# ISP6P5_ISIF register map
Vendor: Texas Instruments
Peripheral module from a debugger description file (folder TDA2Px).
Registers are 32-bit, access per field, reset 0x0 unless marked. A register's access mark holds for its fields unless they carry their own. Offsets are as the file gives them; lines under a group give offsets from that group; [hi:lo] are bit positions; {n}, {i} and the like mark numbered series; 'fields as' and 'values as' point back to an identical list; <NAME> marks a mode.

## ISP6P5_ISIF
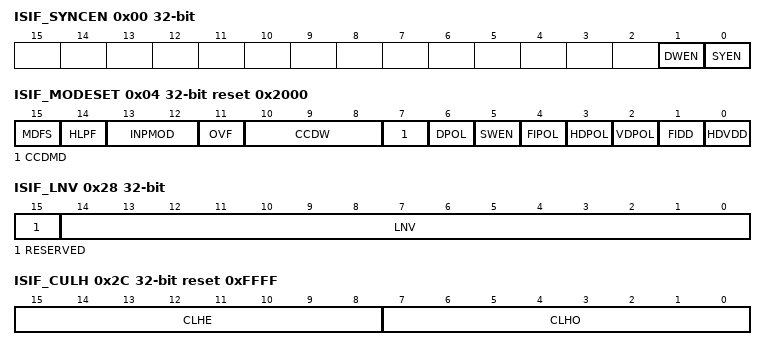
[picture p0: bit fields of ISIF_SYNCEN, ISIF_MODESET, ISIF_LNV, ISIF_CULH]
0x00 ISIF_SYNCEN
  [1] DWEN rw — Controls the storage of image sensor RAW data in memory. This bit is loaded with the timing of the internal VD signal: it becomes active starting at the lead of the VD signal that comes after 1 is written in this bit.
    0=NEWENUM1 (Disable); 1=NEWENUM2 (Enable)
  [0] SYEN rw — Controls ON/OFF of VD/HD output. Internal timing generator becomes active and VD/HD output begins starting when 1 is written in this bit. In case of input, VD/HD loading begins.
    0=NEWENUM1 (Disable); 1=NEWENUM2 (Enable)
0x04 ISIF_MODESET reset 0x2000
  [15] MDFS ro — Field Status This bit indicates the status of the current FLD signal when the ISIF module is in interlaced mode.
    0=NEWENUM1 (Odd field); 1=NEWENUM2 (Even field)
  [14] HLPF rw — Low pass filter enable. When this bit is enabled, a 3-tap (1/4 + 1/2 Z^-2 + 1/4 Z^?4) filtering process is performed on the sensor data.
    0=NEWENUM1 (Disable); 1=NEWENUM2 (Enable)
  [13:12] INPMOD rw — Data input mode:
    0=NEWENUM1 (RAW data); 1=NEWENUM2 (YCbCr 16bit); 3=NEWENUM4 (Reserved); 2=NEWENUM3 (YCbCr 8bit)
  [11] OVF rw — ISIF module write port overflow status bit If the write port of the ISIF module overflows when writing data to SDRAM, this bit will toggle. In OMAP4430 ES1.0, an interrupt (ISIF_OVF) is added to reflect the status of this bit and avoid polling.
    0=NEWENUM1 (No overflow pending (r) No action (w)); 1=NEWENUM2 (Overflow pending (r) Clear overflow (w))
  [10:8] CCDW rw — This bit enables to shift right (divide) the up-to-12-bit RAW data value when writing out to SDRAM. The effect is that the dynamic of the output signal is decreased. TheISIF_MODESET.CCDW, ISIF_HSIZE.ADCR, ISIF_HSIZE.HSIZE, ISIF_CCDCFG.BSWD, ISIF_CCDCFG.MSBINV, ISIF_CCDCFG.SDRPACK bit fields control how pixel data are stored to SDRAM.
    6=NEWENUM7 (Reserved); 1=NEWENUM2 (1-bit right shift out[15:0] = 00000 data[11:1]); 7=NEWENUM8 (Reserved); 0=NEWENUM1 (No shift out[15:0] = 0000 data[11:0]); 2=NEWENUM3 (2-bit right shift out[15:0] = 000000 data[11:2]); 4=NEWENUM5 (4-bit right shift out[15:0] = 00000000 data[11:4]); 5=NEWENUM6 (Reserved); 3=NEWENUM4 (3-bit right shift out[15:0] = 0000000 data[11:3])
  [7] CCDMD rw — Field mode: This bit selects the type of image sensor: interlaced or progressive
    0=NEWENUM1 (Progressive image sensor); 1=NEWENUM2 (Interlaced image sensor)
  [6] DPOL rw — Image sensor input data polarity
    0=NEWENUM1 (No change); 1=NEWENUM2 (One's complement)
  [5] SWEN rw — External WEN selection In case this bit and SYNCEN.DWEN are set to 1, the external WEN signal is used to store image sensor data to memory.
    0=NEWENUM1 (WEN not used); 1=NEWENUM2 (Use external WEN)
  [4] FIPOL rw — FLD Signal Polarity
    0=NEWENUM1 (Positive); 1=NEWENUM2 (Negative)
  [3] HDPOL rw — HD Sync Signal Polarity
    0=NEWENUM1 (Positive); 1=NEWENUM2 (Negative)
  [2] VDPOL rw — VD Sync Signal Polarity
    0=NEWENUM1 (Positive); 1=NEWENUM2 (Negative)
  [1] FIDD rw — FLD Signal Direction There shall be at least three clock cycles between the time this bit is modified and the HD/VD pulse for start of frame comes.
    0=NEWENUM1 (Input); 1=NEWENUM2 (Output)
  [0] HDVDD rw — VD,HD Sync Signal Direction There shall be at least three clock cycles between the time this bit is modified and the HD/VD pulse for start of frame comes.
    0=NEWENUM1 (Input); 1=NEWENUM2 (Output)
0x08 ISIF_HDW
  [11:0] HDW rw — HD width: Sets width of HD. HD width = HDW + 1 clock
0x0C ISIF_VDW
  [11:0] VDW rw — VD width : Sets width of VD. VD width = VDW + 1 line
0x10 ISIF_PPLN
  [15:0] PPLN rw — Pixels per line Number of pixel clock periods in one line HD period = PPLN+1 pixel clocks. PPLN is not used when HD and VD are inputs, i.e. when VDHDOUT in MODESET is cleared to '0'. *This bit field is latched by VD.
0x14 ISIF_LPFR — Line per Frame/Field
  [15:0] LPFR rw — Half lines per filed or frame Sets number of half lines per frame or field. VD period = (LPFR+1)/2 lines. LPFR is not used when HD and are inputs, i.e. when VDHDOUT in MODESET is cleared to '0'. *This bit field is latched by VD.
0x18 ISIF_SPH — Start Pixel Horizontal
  [14:0] SPH rw — The first pixel in a line to be stored to memory.
0x1C ISIF_LNH
  [14:0] LNH rw — Number of pixels in an line to be stored to memory. Number of pixels = LNH + 1. The number of pixels actually written to SDRAM is always a multiple of 16. For example, if CULH=0xFFFF, the actual number of output is 16 x floor((LNH+1)/16). If CULH is not 0xFFFF, the actual output is 16 x floor(w/16), where w is the number of pixels after horizontal culling specified by CULH.
0x20 ISIF_SLV0
  [14:0] SLV0 rw — Start Line, Vertical (Field 0) Sets line at which data output to SDRAM will begin, measured from the start of VD *This bit field is latched by VD.
0x24 ISIF_SLV1
  [14:0] SLV1 rw — Start Line, Vertical (Field 1) Sets line at which data output to SDRAM will begin, measured from the start of VD *This bit field is latched by VD.
0x28 ISIF_LNV
  [15] RESERVED ro — The number of lines to be stored to SDRAM.
  [14:0] LNV rw — The number of lines to be stored to memory. Number of lines = LNV + 1
0x2C ISIF_CULH reset 0xFFFF — This register specifies horizontal culling. Please also refer to for the effect to the number of pixels written to SDRAM.
  [15:8] CLHE rw — Culling Pattern in EVEN Line: Sets culling pattern when data is loaded into memory (even lines). Example:0xAA: 1 / 2 horizontal direction culling. LSB becomes left side on screen.
    0=NEWENUM1 (Pixel invalid); 1=NEWENUM2 (Pixel valid)
  [7:0] CLHO rw — Culling Pattern in ODD Line: Sets culling pattern when data is loaded into memory (odd lines).
    0=NEWENUM1 (Pixel invalid); 1=NEWENUM2 (Pixel valid)
0x30 ISIF_CULV reset 0xFF
  [7:0] CULV rw — Culling Pattern in Vertical Line Note: CULV[0] must be 1 for proper operation. Example:0x11: 1/4 vertical direction culling. LSB becomes top side on screen.
    0=NEWENUM1 (Pixel invalid); 1=NEWENUM2 (Pixel valid)
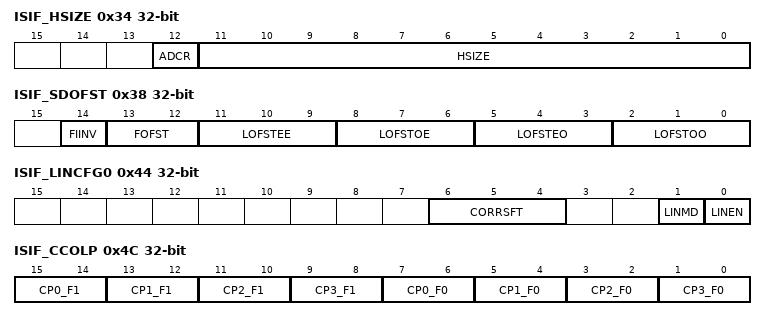
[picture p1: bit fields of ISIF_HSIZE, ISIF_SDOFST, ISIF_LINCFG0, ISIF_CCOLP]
0x34 ISIF_HSIZE — SDRAM OUTPUT CTRL REGISTER
  [12] ADCR rw — SDRAM address decrement. By setting this bit, memory address in a line is automatically decreased so that a line can be Horizontally flipped in memory. TheISIF_MODESET.CCDW, ISIF_HSIZE.ADCR, ISIF_HSIZE.HSIZE, ISIF_CCDCFG.BSWD, ISIF_CCDCFG.MSBINV, ISIF_CCDCFG.SDRPACK bit fields control how pixel data are stored to SDRAM.
    0=NEWENUM1 (Address increment.); 1=NEWENUM2 (Address decrement.)
  [11:0] HSIZE rw — Memory address offset between the lines. Specify the offset in 32-byte units.
0x38 ISIF_SDOFST — SDRAM OUTPUT CTRL REGISTER
  [14] FIINV rw — FID polarity: This bit inverse a FID polarity.
    0=NEWENUM1 (No change); 1=NEWENUM2 (Inverse FID)
  [13:12] FOFST rw — Field line offset value in odd (FID = 1) field
    0=NEWENUM1 (+1 line); 1=NEWENUM2 (+2 lines); 3=NEWENUM4 (+4 lines); 2=NEWENUM3 (+3 lines)
  [11:9] LOFSTEE rw — Field line offset value applied after even line, even field (This value affects the first address of odd lines)
    6=NEWENUM7 (- 3 lines); 1=NEWENUM2 (+2 lines); 7=NEWENUM8 (- 4 lines); 0=NEWENUM1 (+1 line); 2=NEWENUM3 (+3 lines); 4=NEWENUM5 (- 1 line); 5=NEWENUM6 (- 2 lines); 3=NEWENUM4 (+4 lines)
  [8:6] LOFSTOE rw — Field line offset value applied after odd line, even field (This value affects the even lines)
    values as LOFSTEE
  [5:3] LOFSTEO rw — Field line offset value applied after even line, odd field (This value affects the first address of off lines)
    values as LOFSTEE
  [2:0] LOFSTOO rw — Field line offset value applied after odd line, odd field (This value affects the first address of even lines)
    values as LOFSTEE
0x3C ISIF_CADU — SDRAM OUTPUT CTRL REGISTER
  [10:0] CADU rw — Memory Address (Upper 11-bits): Specifies the memory destination address. The actual address is the value set here multiplied by 32bytes.
0x40 ISIF_CADL — SDRAM OUTPUT CTRL REGISTER
  [15:0] CADL rw — Memory Address (Lower 16-bits): Specifies the memory destination address. The actual address is the value set here multiplied by 32bytes.
0x44 ISIF_LINCFG0 — INPUT LINEARIZATION CTRL REGISTER
  [6:4] CORRSFT rw — Shift up value for the correction value (S10).
    {v}=NEWENUM{v+1} ({v}-bit left shift) (v=1..6); 7=NEWENUM8 (Reserved); 0=NEWENUM1 (No shift)
  [1] LINMD rw — Linearization Mode:
    0=NEWENUM1 (Uniform sampling); 1=NEWENUM2 (Non-uniform sampling)
  [0] LINEN rw — Linearization Enable:
    0=NEWENUM1 (Disable); 1=NEWENUM2 (Enable)
0x48 ISIF_LINCFG1 reset 0x400 — INPUT LINEARIZATION CTRL REGISTER
  [10:0] LUTSCL rw — Scale factor (U11Q10) for LUT input. Range: 0 ? 1+1023/1024 It?s applied to the Input Data before looking up the correction factor. The scale factor is only applied to the table input. It?s not applied when using the input value to compute the output.
0x4C ISIF_CCOLP
  [all] fields
    0=NEWENUM1 (R / Ye); 1=NEWENUM2 (Gr / Cy); 3=NEWENUM4 (B / Mg); 2=NEWENUM3 (Gb / G)
  [15:14] CP0_F1 rw — Specifies color pattern for pixel position 0 (Field 1) Pixel position 0 corresponds to pixel count=0 at even line in case of CFAP=?0?, and to pixel count=0 in case of CFAP=?1?.
  [13:12] CP1_F1 rw — Specifies color pattern for pixel position 1 (Field 1) Pixel position 1 corresponds to pixel count=1 at even line in case of CFAP=?0?, and to pixel count=1 in case of CFAP=?1?.
  [11:10] CP2_F1 rw — Specifies color pattern for pixel position 2 (Field 1) Pixel position 2 corresponds to pixel count=0 at odd line in case of CFAP=?0?, and to pixel count=2 in case of CFAP=?1?.
  [9:8] CP3_F1 rw — Specifies color pattern for pixel position 3 (Field 1) Pixel position 3 corresponds to pixel count=1 at odd line in case of CFAP=?0?. Not applicable for CFAP=?1?.
  [7:6] CP0_F0 rw — Specifies color pattern for pixel position 0 (Field 0) Pixel position 0 corresponds to pixel count=0 at even line in case of CFAP=?0?, and to pixel count=0 in case of CFAP=?1?.
  [5:4] CP1_F0 rw — Specifies color pattern for pixel position 1 (Field 0) Pixel position 1 corresponds to pixel count=1 at even line in case of CFAP=?0?, and to pixel count=1 in case of CFAP=?1?.
  [3:2] CP2_F0 rw — Specifies color pattern for pixel position 2 (Field 0) Pixel position 2 corresponds to pixel count=0 at odd line in case of CFAP=?0?, and to pixel count=2 in case of CFAP=?1?.
  [1:0] CP3_F0 rw — Specifies color pattern for pixel position 3 (Field 0) Pixel position 3 corresponds to pixel count=1 at odd line in case of CFAP=?0?. Not applicable for CFAP=?1?.
0x50 ISIF_CRGAIN reset 0x200
  [11:0] CGR rw — R/Ye gain: Performs gain adjustment on image sensor data. U12Q9. Range: 0 ? 7+511/512
0x54 ISIF_CGRGAIN reset 0x200
  [11:0] CGGR rw — Gr/Cy gain: Performs gain adjustment on image sensor data. U12Q9. Range: 0 ? 7+511/512
0x58 ISIF_CGBGAIN reset 0x200
  [11:0] CGGB rw — Gb/Cy gain: Performs gain adjustment on image sensor data. U12Q9. Range: 0 ? 7+511/512
0x5C ISIF_CBGAIN reset 0x200
  [11:0] CGB rw — B/Mg gain: Performs gain adjustment on image sensor data. U12Q9. Range: 0 ? 7+511/512
0x60 ISIF_COFSTA
  [11:0] COFT rw — Image sensor offset: Performs offset value adjustment on image sensor data (0~4095).
0x64 ISIF_FLSHCFG0 — Not used in MONICA and OMAP4
  [0] FLSHEN rw — Flash timing signal enable This bit is automatically cleared to '0' at VD timing.
    0=NEWENUM1 (Disable); 1=NEWENUM2 (Enable)
0x68 ISIF_FLSHCFG1 — Not used in MONICA and OMAP4
  [14:0] SFLSH rw — Start line to set the FLASH timing signal.
0x6C ISIF_FLSHCFG2 — Not used in MONICA and OMAP4
  [15:0] VFLSH rw — Valid width of the FLASH timing signal. Valid width = Crystal-clock x 2 x (VFLSH + 1)
{0x70+4i} ISIF_VDINT{i} (i=0..2)
  [14:0] CVD{i} rw — VD{i} Interrupt timing in a field (line number).
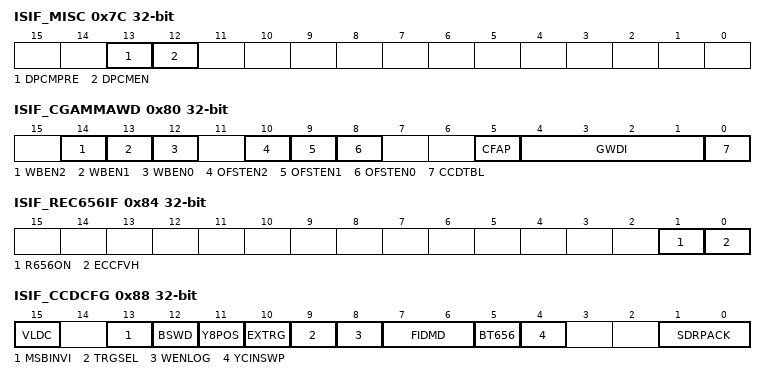
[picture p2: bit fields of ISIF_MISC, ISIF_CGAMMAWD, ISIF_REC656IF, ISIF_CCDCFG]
0x7C ISIF_MISC
  [13] DPCMPRE rw — Selects Predictor for DPCM Encoder (12-8)
    0=NEWENUM1 (Predictor 1); 1=NEWENUM2 (Predictor 2)
  [12] DPCMEN rw — Enables DPCM Encoding (12-8)
    0=NEWENUM1 (Disable); 1=NEWENUM2 (Enable)
0x80 ISIF_CGAMMAWD
  [14] WBEN2 rw — White Balance Enable for H3A
    0=NEWENUM1 (Disable); 1=NEWENUM2 (Enable)
  [13] WBEN1 rw — White Balance Enable for IPIPE
    0=NEWENUM1 (Disable); 1=NEWENUM2 (Enable)
  [12] WBEN0 rw — White Balance Enable for memory capture
    0=NEWENUM1 (Disable); 1=NEWENUM2 (Enable)
  [10] OFSTEN2 rw — Offset control Enable for H3A
    0=NEWENUM1 (Disable); 1=NEWENUM2 (Enable)
  [9] OFSTEN1 rw — Offset control Enable for IPIPE
    0=NEWENUM1 (Disable); 1=NEWENUM2 (Enable)
  [8] OFSTEN0 rw — Offset control Enable for SDRAM capture
    0=NEWENUM1 (Disable); 1=NEWENUM2 (Enable)
  [5] CFAP rw — Selects CFA pattern
    0=NEWENUM1 (Mosaic color pattern. It should look like this. G R G R G R G R G R . . . B G B G B G B G B G . . . G R G R G R G R G R . . . . . . . . . . . . . . . . . . . . . . . . . . . . . . . . .); 1=NEWENUM2 (Stripe color pattern. It should look like this. R G B R G B R G B . . . R G B R G B R G B . . . R G B R G B R G B . . . . . . . . . . . . . . . . . . . . . . . . . . . . . . . . .)
  [4:1] GWDI rw — Selects MSB position of Input Data
    {v}=NEWENUM{v+1} (Reserved) (v=9..15); 1=NEWENUM2 (bit 14); 7=NEWENUM8 (bit 8); 6=NEWENUM7 (bit 9); 0=NEWENUM1 (bit 15); 5=NEWENUM6 (bit 10); 4=NEWENUM5 (bit 11); 2=NEWENUM3 (bit 13); 3=NEWENUM4 (bit 12); 8=NEWENUM9 (bit 7)
  [0] CCDTBL rw — On/Off control of A-law table for SDRAM capture
    0=NEWENUM1 (Disable); 1=NEWENUM2 (Enable)
0x84 ISIF_REC656IF — INPUT CONFIG REGISTER
  [1] R656ON rw — CCIR Rec.656 interface mode
    0=NEWENUM1 (Disable); 1=NEWENUM2 (Enable)
  [0] ECCFVH rw — Error correction of FVH code
    0=NEWENUM1 (Disable); 1=NEWENUM2 (Enable)
0x88 ISIF_CCDCFG
  [15] VLDC rw — On/off control of CPU registers re-synchronize function by VSYNC. All the others are shadowed registers, where register values are updated at V-sync timing by default. If VDLC=1, ISIF register values are updated immediately after register write just like non-shadowed registers.
    0=NEWENUM1 (Enable); 1=NEWENUM2 (Disable)
  [13] MSBINVI rw — MSB inverse of CIN port when the data are captured to SDRAM. TheISIF_MODESET.CCDW, ISIF_HSIZE.ADCR, ISIF_HSIZE.HSIZE, ISIF_CCDCFG.BSWD, ISIF_CCDCFG.MSBINV, ISIF_CCDCFG.SDRPACK bit fields control how pixel data are stored to SDRAM.
    0=NEWENUM1 (Disable); 1=NEWENUM2 (Enable)
  [12] BSWD rw — On/off control of Byte SWAP function when SDRAM capturing. TheISIF_MODESET.CCDW, ISIF_HSIZE.ADCR, ISIF_HSIZE.HSIZE, ISIF_CCDCFG.BSWD, ISIF_CCDCFG.MSBINV, ISIF_CCDCFG.SDRPACK bit fields control how pixel data are stored to SDRAM.
    0=NEWENUM1 (Disable); 1=NEWENUM2 (Enable (swap))
  [11] Y8POS rw — Selects Y signal position when in 8bit input mode
    0=NEWENUM1 (even pixel); 1=NEWENUM2 (odd pixel)
  [10] EXTRG rw — Setting ?1? to this register, the SDRAM address is initialized at the rising edge of FID input signal or DWEN register.
  [9] TRGSEL rw — Select trigger source signal of SDRAM address initializing in case EXTRG=1.
    0=NEWENUM1 (DWEN register); 1=NEWENUM2 (FID input port)
  [8] WENLOG rw — Specifies the CCD valid area.
    0=NEWENUM1 (internal valid signal and WEN signal is ANDed logically.); 1=NEWENUM2 (internal valid signal and WEN signal is ORed logically.)
  [7:6] FIDMD rw — Specifies FID detection mode
    0=NEWENUM1 (latch the FID at the VSYNC timing); 1=NEWENUM2 (no latch the FID); 3=NEWENUM4 (Reserved); 2=NEWENUM3 (Reserved)
  [5] BT656 rw — Selects bit width of CCIR656. This bit applies only ifISIF_REC656IF.R656ON = 1.
    0=NEWENUM1 (8 bits); 1=NEWENUM2 (10 bits)
  [4] YCINSWP rw — The ISIF module has a 16-bit interface. When 16-bit YUV data are input, the luma data (YIN7-0) are expected to be on the 8 MS bits and the chroma (CIN7-0) data are expected to be on the LS bits. This bit enables to swap the 8 MS bits with the 8 LS bits of the interface in case the luma and chroma do not come in the correct order. Refer to the top-level ISIF block diagram.
    0=NEWENUM1 (YIN7-0 = Y signal / CIN7-0 = C signal); 1=NEWENUM2 (YIN7-0 = C signal / CIN7-0 = Y signal)
  [1:0] SDRPACK rw — This bit field selects how the data are stored to SDRAM. There can be 8, 12 or 16 bits per pixel. TheISIF_MODESET.CCDW, ISIF_HSIZE.ADCR, ISIF_HSIZE.HSIZE, ISIF_CCDCFG.BSWD, ISIF_CCDCFG.MSBINV, ISIF_CCDCFG.SDRPACK bit fields control how pixel data are stored to SDRAM.
    0=NEWENUM1 (16 bits / pixel); 1=NEWENUM2 (12 bits / pixel); 3=NEWENUM4 (Reserved); 2=NEWENUM3 (8 bits / pixel)
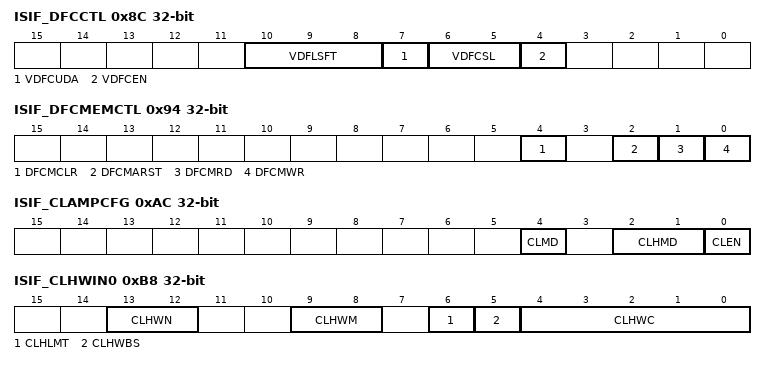
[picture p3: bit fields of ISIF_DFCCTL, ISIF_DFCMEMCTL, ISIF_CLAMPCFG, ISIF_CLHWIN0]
0x8C ISIF_DFCCTL — VERTICAL LINE DEFCT CTRL REGISTER
  [10:8] VDFLSFT rw — Vertical line Defect level shift value Defect Level (value to be subtracted from the data) is 8bit width, but can be up-shifted up to 6bits by VDFLSFT. Left shift value = VDFLSFT (Range: 0-6) Setting 7 to VDFLSFT is not allowed.
  [7] VDFCUDA rw — Vertical line Defect Correction upper pixels disable.
    0=NEWENUM1 (The whole line is corrected.); 1=NEWENUM2 (Pixels upper than the defect are not corrected.)
  [6:5] VDFCSL rw — Vertical line Defect Correction mode select.
    0=NEWENUM1 (Defect level subtraction. Just fed through if data are saturating.); 1=NEWENUM2 (Defect level subtraction. Horizontal interpolation ((i-2)+(i+2))/2 if data are saturating.); 3=NEWENUM4 (Reserved); 2=NEWENUM3 (Horizontal interpolation ((i-2)+(i+2))/2.)
  [4] VDFCEN rw — Vertical line Defect Correction enable. This bit field is latched by VD.
    0=NEWENUM1 (Disable); 1=NEWENUM2 (Enable)
0x90 ISIF_VDFSATLV — VERTICAL LINE DEFCT CTRL REGISTER
  [11:0] VDFSLV rw — Vertical line Defect Correction saturation level. VDFSLV is U12 (Range: 0 - 4,095).
0x94 ISIF_DFCMEMCTL — VERTICAL LINE DEFCT CTRL REGISTER
  [4] DFCMCLR rw — Defect correction. Memory clear. Writing ?1? to this bit clears the memory contents to all zero. It will be automatically cleared to `0` when the memory clear is completed.
  [2] DFCMARST rw — Defect correction. Memory address reset. Setting DFCMWR or DFCMRD with LSCMARST set starts memory access to address offset 0. DFCMARST is automatically cleared if data transfer completes. Setting DFCMWR or DFCMRD with LSCMARST cleared starts memory access to the next address.
    0=NEWENUM1 (Increment the memory address); 1=NEWENUM2 (Clear the memory address to offset 0)
  [1] DFCMRD rw — Defect correction. Memory read [for debug purpose] Writing ?1? to this bit starts reading from the memory. It will be automatically cleared when the data transfer is completed, and the data can be read from DFCMEM4-0.
  [0] DFCMWR rw — Defect correction. Memory write Writing ?1? to this bit starts writing to the memory. It will be automatically cleared when the data transfer is completed. DFCMEM4-0 should be set prior to the memory access.
0x98 ISIF_DFCMEM0 — Defect correction memory
  [12:0] DFCMEM0 rw — Defect correction memory 0 Sets V position of the defects.
0x9C ISIF_DFCMEM1 — Defect correction memory
  [12:0] DFCMEM1 rw — Defect correction memory 1 Sets H position of the defects.
0xA0 ISIF_DFCMEM2 — Defect correction memory
  [7:0] DFCMEM2 rw — Defect correction Memory 2 Set SUB1: Defect level of the Vertical line defect position (V = Vdefect). DFCMEM2 can be up shifted according to VDFLSFT, and subtracted from the data for Vertical line defect correction.
0xA4 ISIF_DFCMEM3 — Defect correction memory
  [7:0] DFCMEM3 rw — Defect correction Memory 3 Set SUB2: Defect level of the pixels upper than the Vertical line defect (V Vdefect). DFCMEM3 can be up shifted according to VDFLSFT, and subtracted from the data for Vertical line defect correction.
0xA8 ISIF_DFCMEM4 — Defect correction memory
  [7:0] DFCMEM4 rw — Memory 4 Set SUB3: Defect level of the pixels lower than the Vertical line defect (V Vdefect). DFCMEM4 can be up shifted according to VDFLSFT, and subtracted from the data for Vertical line defect correction.
0xAC ISIF_CLAMPCFG — BLACK CLAMP CTRL REGISTER
  [4] CLMD rw — Black clamp mode Clamp value can be calculated regardless of the color or can be calculated separately for each 4 colors.
    0=NEWENUM1 (Clamp value calculated regardless of the pixel color.); 1=NEWENUM2 (Clamp value calculated separately for each 4 colors.)
  [2:1] CLHMD rw — Horizontal Clamp mode
    0=NEWENUM1 (Horizontal clamp disabled. Only the Vertical clamp value is subtracted from the Image data.); 1=NEWENUM2 (Horizontal clamp value calculation enabled. The calculated Horizontal clamp value is subtracted from the Image data along with the Vertical clamp value.); 3=NEWENUM4 (Reserved); 2=NEWENUM3 (Horizontal clamp value not updated. The Horizontal clamp value used for the previous image is subtracted from the Image data along with the Vertical clamp value.)
  [0] CLEN rw — Black Clamp Enable Enables clamp value to be subtracted from Image data.
    0=NEWENUM1 (Disable); 1=NEWENUM2 (Enable)
0xB0 ISIF_CLDCOFST — BLACK CLAMP CTRL REGISTER
  [12:0] CLDC rw — DC offset for black clamp This value is added to the incoming pixels regardless whether optical black clamp is enabled (ISIF_CLAMPCFG.CLEN). This value is in S13Q0 format.
0xB4 ISIF_CLSV — BLACK CLAMP CTRL REGISTER
  [12:0] CLSV rw — Black Clamp Start position (V). Sets the line number where clamp value subtraction starts. Range: 0 - 8191
0xB8 ISIF_CLHWIN0 — BLACK CLAMP CTRL REGISTER
  [13:12] CLHWN rw — Horizontal Black clamp - Vertical dimension of a Window (2^N).
    0=NEWENUM1 (Window is 2 pixels tall (N=1)); 1=NEWENUM2 (Window is 4 pixels tall (N=2)); 3=NEWENUM4 (Window is 16 pixels tall (N=4)); 2=NEWENUM3 (Window is 8 pixels tall (N=3))
  [9:8] CLHWM rw — Horizontal Black clamp - Horizontal dimension of a Window (2^M).
    0=NEWENUM1 (Window is 32 pixels wide (M=5)); 1=NEWENUM2 (Window is 64 pixels wide (M=6)); 3=NEWENUM4 (Window is 256 pixels wide (M=8)); 2=NEWENUM3 (Window is 128 pixels wide (M=7))
  [6] CLHLMT rw — Horizontal Black clamp - Pixel value limitation for the Horizontal clamp value calculation. If this bit is set, the maximum pixel value to be used for the clamp value calculation would be limited to 1023. By setting this bit, the pixel value greater than 1023 will be replaced by the last pixel value which was equal to or less than 1023. In caseISIF_CLAMPCFG.CLMD=1 (4-color mode), the pixel value greater than 1023 will be replaced by the last pixel value of the same color which was equal to or less than 1023.
    0=NEWENUM1 (Limitation disabled); 1=NEWENUM2 (Limitation enabled)
  [5] CLHWBS rw — Horizontal Black clamp - Base Window select
    0=NEWENUM1 (The most left window); 1=NEWENUM2 (The most right window)
  [4:0] CLHWC rw — Horizontal Black clamp - Window count per color Window count = CLHWC+1 Range: 1 - 32
0xBC ISIF_CLHWIN1 — BLACK CLAMP CTRL REGISTER
  [12:0] CLHSH rw — Horizontal black clamp. Window Start position (H). Range: 0 - 8191
0xC0 ISIF_CLHWIN2 — BLACK CLAMP CTRL REGISTER
  [12:0] CLHSV rw — Horizontal black clamp. Window Start position (V). Range: 0 - 8191
0xC4 ISIF_CLVRV — BLACK CLAMP CTRL REGISTER
  [11:0] CLVRV rw — Vertical black clamp reset value. (U12) Range: 0 to 4095
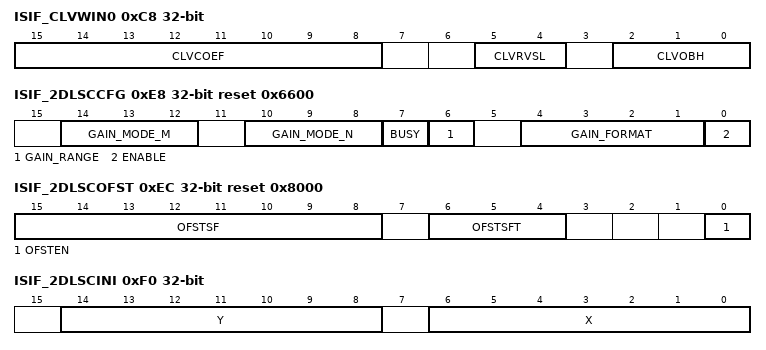
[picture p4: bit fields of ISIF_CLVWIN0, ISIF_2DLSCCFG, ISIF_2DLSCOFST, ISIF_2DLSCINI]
0xC8 ISIF_CLVWIN0 — BLACK CLAMP CTRL REGISTER
  [15:8] CLVCOEF rw — Vertical Black clamp - Line average coefficient (k). Set a coefficient which is applied to the line average for clamp value calculation. (1-k) is applied to the clamp value of the previous line. Vaue in the U8Q8 format, the range is 0 to 255/256.
  [5:4] CLVRVSL rw — Vertical Black clamp - reset value selection Select the reset value for the clamp value of the previous line
    0=NEWENUM1 (The base value calculated for Horizontal direction); 1=NEWENUM2 (Value set via the configuration register); 3=NEWENUM4 (Reserved); 2=NEWENUM3 (No update (same as the previous image))
  [2:0] CLVOBH rw — Vertical Black clamp - Optical Black H valid (2^L).
    6=NEWENUM7 (Reserved); 1=NEWENUM2 (4 pixels wide (L=2)); 7=NEWENUM8 (Reserved); 0=NEWENUM1 (2 pixels wide (L=1)); 2=NEWENUM3 (8 pixels wide (L=3)); 4=NEWENUM5 (32 pixels wide (L=5)); 5=NEWENUM6 (64 pixels wide (L=6)); 3=NEWENUM4 (16 pixels wide (L=4))
0xCC ISIF_CLVWIN1 — BLACK CLAMP CTRL REGISTER
  [12:0] CLVSH rw — Vertical black clamp. Window Start position (H). Range: 0 - 8191
0xD0 ISIF_CLVWIN2 — BLACK CLAMP CTRL REGISTER
  [12:0] CLVSV rw — Vertical black clamp. Window Start position (V). Range: 0 - 8191
0xD4 ISIF_CLVWIN3 — BLACK CLAMP CTRL REGISTER
  [12:0] CLVOBV rw — Vertical black clamp. Optical black V valid (V). Range: 0 - 8191
0xD8 ISIF_LSCHOFST — 2D Lens Shading Correction Register
  [13:0] HOFST rw — H direction Data offset for Lens Shading Correction. Range: 0-16,383 Not valid if the Formatter is enabled.
0xDC ISIF_LSCVOFST — 2D Lens Shading Correction Register
  [13:0] VOFST rw — V direction Data offset for Lens Shading Correction. Range: 0-16,383
0xE0 ISIF_LSCHVAL — 2D Lens Shading Correction Register
  [13:0] HVAL rw — Number of valid pixels in H direction. HVAL is for LSC. Number of valid pixels = HVAL+ 1
0xE4 ISIF_LSCVVAL — 2D Lens Shading Correction Register
  [13:0] VVAL rw — Number of valid lines in V direction. VVAL is for LSC. Number of valid lines = VVAL+ 1
0xE8 ISIF_2DLSCCFG reset 0x6600 — 2D Lens Shading Correction Register
  [14:12] GAIN_MODE_M rw — Define the horizontal dimension of a paxel. Possible values are listed below.
    6=NEWENUM7 (Paxel is 64 pixels tall (M=64)); 1=NEWENUM2 (Reserved); 7=NEWENUM8 (Paxel is 128 pixels tall (M=128)); 0=NEWENUM1 (Reserved); 2=NEWENUM3 (Reserved); 4=NEWENUM5 (Paxel is 16 pixels tall (M=16)); 5=NEWENUM6 (Paxel is 32 pixels tall (M=32)); 3=NEWENUM4 (Paxel is 8 pixels tall (M=8))
  [10:8] GAIN_MODE_N rw — Define the vertical dimension of a paxel. Possible values are listed below.
    6=NEWENUM7 (Paxel is 64 pixels tall (N=64)); 1=NEWENUM2 (Reserved); 7=NEWENUM8 (Paxel is 128 pixels tall (N=128)); 0=NEWENUM1 (Reserved); 2=NEWENUM3 (Reserved); 4=NEWENUM5 (Paxel is 16 pixels tall (N=16)); 5=NEWENUM6 (Paxel is 32 pixels tall (N=32)); 3=NEWENUM4 (Paxel is 8 pixels tall (N=8))
  [7] BUSY ro — Busy bit
    0=NEWENUM1 (Idle); 1=NEWENUM2 (Busy)
  [6] GAIN_RANGE rw — Define the range of gain table values. 0: 8-bit gain mode, GAIN table represents unsigned 8bit values 1: 16-bit gain mode. GAIN table is combined with OFST table to constitute 16 bit gain values. GAIN table represents MSB 8 bits, and OFST table represents LSB 8 bits. In 16-bit, offset table is loaded from memory. Offset control function is disabled. (OFSTEN is treated as zero in this mode.) This function is only for OMAP5430-ISP.
  [4:1] GAIN_FORMAT rw — Sets gain table format 16-bit mode is only for OMAP5430. For OMAP4, only 8-bit mode is available.
    13=NEWENUM14 (In 8-bit mode, Coded as 2-bit integer, 6-bit fraction + 1.0, Range from 1 to 4+63/64 In 16-bit mode, Coded as 6-bit integer and 10-bit fraction Range from 1 to 64+1023/1024); 1=NEWENUM2 (In 8-bit mode, Coded as 8-bit fraction + 1.0 of base, Range from 1 to 1+255/256 in 16-bit mode, Coded as 16-bit fraction + 1.0 of base, Range from 1 to 1+65535/65536); 7=NEWENUM8 (In 8-bit mode, Coded as 3-bit integer, 5-bit fraction + 1.0, Range from 1 to 8+31/32 In 16-bit mode, Coded as 3-bit integer, 13-bit fraction + 1.0, Range from 1 to 8+8191/8192); 6=NEWENUM7 (In 8-bit mode, Coded as 3-bit integer, 5-bit fraction, Range from 0 to 7+31/32 In 16-bit mode, Coded as 3-bit integer, 13-bit fraction, Range from 0 to 7+8191/8192); 0=NEWENUM1 (In 8-bit mode, Coded as 8-bit fraction Range from 0 to 255/256 In 16-bit mode, Coded as 16-bit fraction Range from 0 to 65535/65536); 5=NEWENUM6 (In 8-bit mode, Coded as 2-bit integer, 6-bit fraction + 1.0, Range from 1 to 4+63/64 In 16-bit mode, Coded as 2-bit integer, 14-bit fraction + 1.0, Range from 1 to 4+16383/16384); 10=NEWENUM11 (In 8-bit mode, Coded as 1-bit integer, 7-bit fraction, Range from 0 to 1+127/128 In 16-bit mode, Coded as 5-bit integer and 11-bit fraction Range from 0 to 31+2047/2048); 9=NEWENUM10 (In 8-bit mode, Coded as 8-bit fraction + 1.0 of base, Range from 1 to 1+255/256 In 16-bit mode, Coded as 4-bit integer and 12-bit fraction Range from 1 to 16+4095/4096); 11=NEWENUM12 (In 8-bit mode, Coded as 1-bit integer, 7-bit fraction + 1.0, Range from 1 to 2+127/128 In 16-bit mode, Coded as 5-bit integer and 11-bit fraction + 1.0, Range from 1 to 32+2047/2048); 4=NEWENUM5 (In 8-bit mode, Coded as 2-bit integer, 6-bit fraction, Range from 0 to 3+63/64 In 16-bit mode, Coded as 2-bit integer, 14-bit fraction, Range from 0 to 3+16383/16384); 2=NEWENUM3 (In 8-bit mode, Coded as 1-bit integer, 7-bit fraction, Range from 0 to 1+127/128 In 16-bit mode, Coded as 1-bit integer, 15-bit fraction, Range from 0 to 1+32767/32768); 15=NEWENUM16 (In 8-bit mode, Coded as 3-bit integer, 5-bit fraction + 1.0, Range from 1 to 8+31/32 In 16-bit mode, Coded as 7-bit integer and 9-bit fraction + 1.0, Range from 1 to 128+511/512); 12=NEWENUM13 (In 8-bit mode, Coded as 2-bit integer, 6-bit fraction, Range from 0 to 3+63/64 In 16-bit mode, Coded as 6-bit integer and 10-bit fraction Range from 0 to 63+1023/1024); 3=NEWENUM4 (In 8-bit mode, Coded as 1-bit integer, 7-bit fraction + 1.0, Range from 1 to 2+127/128 In 16-bit mode, Coded as 1-bit integer, 15-bit fraction + 1.0, Range from 1 to 2+32767/32768); 8=NEWENUM9 (In 8-bit mode, Coded as 8-bit fraction Range from 0 to 255/256 In 16-bit mode, Coded as 4-bit integer and 12-bit fraction Range from 0 to 15+4095/4096); 14=NEWENUM15 (In 8-bit mode, Coded as 3-bit integer, 5-bit fraction, Range from 0 to 7+31/32 In 16-bit mode, Coded as 7-bit integer and 9-bit fraction Range from 0 to 127+511/512)
  [0] ENABLE rw — Enables/disables LSC
    0=NEWENUM1 (Disables the module at the end of the current frame.); 1=NEWENUM2 (Enables the module.)
0xEC ISIF_2DLSCOFST reset 0x8000 — 2D Lens Shading Correction Register
  [15:8] OFSTSF rw — Scaling factor for Offsets (U8Q7) Range: 0 to 1+127/128
  [6:4] OFSTSFT rw — Shift up value for Offsets (S8Q0)
    6=NEWENUM7 (Reserved); 1=NEWENUM2 (1bit left shift); 7=NEWENUM8 (Reserved); 0=NEWENUM1 (No shift); {v}=NEWENUM{v+1} ({v}bits left shift) (v=2..5)
  [0] OFSTEN rw — Enables/disables Offset control in LSC This bit is ignored (treated as zero) in 16-bit gain mode (ISIF_2DLSCCFG.GAIN_RANGE=1). In 16-bit, offset table is loaded from memory, and used as lower 8-bit of 16-bit gain table.
    0=NEWENUM1 (Disable); 1=NEWENUM2 (Enable)
0xF0 ISIF_2DLSCINI — 2D Lens Shading Correction Register
  [14:8] Y rw — Initial Y Y position, in pixels, of the first active pixel in reference to the first active paxel. Must be an even number.
  [6:0] X rw — Initial X X position, in pixels, of the first active pixel in reference to the first active paxel. Must be an even number.
0xF4 ISIF_2DLSCGRBU — 2D Lens Shading Correction Register
  [15:0] BASE31_16 rw — Gain Table address base (Upper 16-bits) This bit field sets the address of the gain table in memory. Table address in bytes. Table is 32-bit aligned so this register must be a multiple of 4.
0xF8 ISIF_2DLSCGRBL — 2D Lens Shading Correction Register
  [15:0] BASE15_0 rw — Gain Table address base (Lower 16-bits) Table address in bytes. This bit field sets the address of the gain table in memory. Table is 32-bit aligned so this register must be a multiple of 4.
0xFC ISIF_2DLSCGROF — 2D Lens Shading Correction Register
  [15:0] OFFSET rw — Gain Table offset Defines the length, in bytes, of one row of the table. Table is 32-bit aligned so this register must be a multiple of 4. Note that the row in memory could be longer than what LSC uses.
0x100 ISIF_2DLSCORBU — 2D Lens Shading Correction Register
  [15:0] BASE rw — Offset Table address base (Upper 16-bits) Table address in bytes. This bit field sets the address of the gain table in memory. Table is 32-bit aligned so this register must be a multiple of 4.
0x104 ISIF_2DLSCORBL — 2D Lens Shading Correction Register
  [15:0] BASE rw — Offset Table address base (Lower 16-bits) Table address in bytes. This bit field sets the address of the gain table in memory. Table is 32-bit aligned so this register must be a multiple of 4.
0x108 ISIF_2DLSCOROF — 2D Lens Shading Correction Register
  [15:0] OFFSET rw — Offset Table offset Defines the length, in bytes, of one row of the table. Note that the row in memory could be longer than what LSC uses. Table is 32-bit aligned so this register must be a multiple of 4.
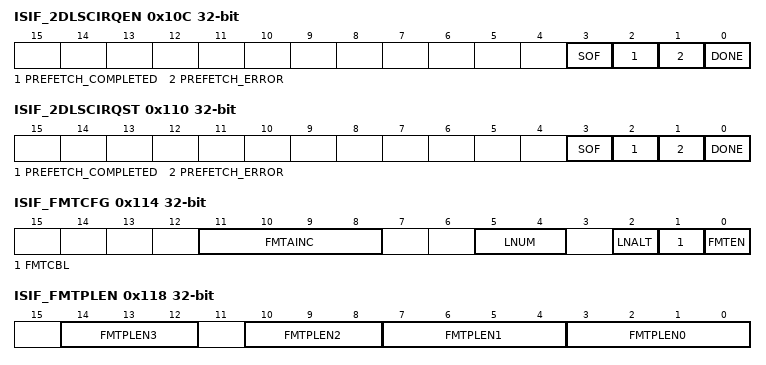
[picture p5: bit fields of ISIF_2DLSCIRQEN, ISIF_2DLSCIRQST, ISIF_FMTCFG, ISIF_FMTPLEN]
0x10C ISIF_2DLSCIRQEN
  [all] fields
    0=NEWENUM1 (Interrupt is masked); 1=NEWENUM2 (Interrupt is enabled)
  [3] SOF rw — Interrupt status for LSC SOF Indicates the start of the LSC valid region. LSC configuration registers can be updated after LSC SOF for the next frame.
  [2] PREFETCH_COMPLETED rw — Interrupt enable for Prefetch Complete Indicates current state of the prefetch buffer. Could be used to start sending the data once the buffer is full to minimize the risk of an underflow. This event is triggered when the buffer contains 3 full paxel rows.
  [1] PREFETCH_ERROR rw — Interrupt enable for Prefetch Error The prefetch error indicates when the gain table was read to slowly from SDRAM. When this event is pending the module goes into transparent mode (output=input). Normal operation can be resumed at the start of the next frame after 1) clearing this event 2) disabling the LSC module 3) enabling it
  [0] DONE rw — Interrupt enable for LSC Done The event is triggered when the internal state of LSC toggles from BUSY to IDLE.
0x110 ISIF_2DLSCIRQST — 2D Lens Shading Correction Register
  [all] fields
    0=NEWENUM1 (Event is not pending (r) Bit remains unchanged (w)); 1=NEWENUM2 (Event is pending (r) Event is cleared (w))
  [3] SOF rw — Interrupt status for LSC SOF Indicates the start of the LSC valid region. LSC configuration registers can be updated after LSC SOF for the next frame.
  [2] PREFETCH_COMPLETED rw — Interrupt status for Prefetch Complete Indicates current state of the prefetch buffer. Could be used to start sending the data once the buffer is full to minimize the risk of an underflow. This event is triggered when the buffer contains 3 full paxel rows. It could be used to minimize buffer underflow risks.
  [1] PREFETCH_ERROR rw — Interrupt status for Prefetch Error The prefetch error indicates when the gain table was read to slowly from SDRAM. When this event is pending the module goes into transparent mode (output=input). Normal operation can be resumed at the start of the next frame after 1) clearing this event 2) disabling the LSC module 3) enabling it
  [0] DONE rw — Interrupt status for LSC Done The event is triggered when the internal state of LSC toggles from BUSY to IDLE.
0x114 ISIF_FMTCFG — Input Data Formatter Register
  [11:8] FMTAINC rw — Address increment Address increment = (FMTAINC + 1) Range (1-16) *This bit is latched by VD.
  [5:4] LNUM rw — Split/Combine number of lines *This bit is latched by VD.
    0=NEWENUM1 (1 output line); 1=NEWENUM2 (1 input line - 2 output lines (FMTCBL=0) 2 input lines - 1 output line (FMTCBL=1)); 3=NEWENUM4 (1 input line - 4 output lines (FMTCBL=0) 4 input lines - 1 output line (FMTCBL=1)); 2=NEWENUM3 (1 input line - 3 output lines (FMTCBL=0) 3 input lines - 1 output line (FMTCBL=1))
  [2] LNALT rw — Line alternating *This bit is latched by VD.
    0=NEWENUM1 (Normal mode); 1=NEWENUM2 (Line alternative mode)
  [1] FMTCBL rw — Combine Input lines *This bit is latched by VD.
    0=NEWENUM1 (Split 1 input line into multiple output lines); 1=NEWENUM2 (Combine multiple input lines into 1 output line)
  [0] FMTEN rw — CCD Formatter enable *This bit is latched by VD.
    0=NEWENUM1 (Disable); 1=NEWENUM2 (Enable)
0x118 ISIF_FMTPLEN — Input Data Formatter Register
  [14:12] FMTPLEN3 rw — Number of program entries for SET3 Number of entries = (FMTPLEN3 + 1) Range: 1-8 Valid only if FMTCBL is set *This bit is latched by VD.
  [10:8] FMTPLEN2 rw — Number of program entries for SET2 Number of entries = (FMTPLEN2 + 1) Range: 1-8 Valid only if FMTCBL is set *This bit is latched by VD.
  [7:4] FMTPLEN1 rw — Number of program entries for SET1 Number of entries = (FMTPLEN1 + 1) Range: 1-16 (FMTCBL = 0) 1-8 (FMTCBL = 1) Setting a value greater than 7 to FMTPLEN1 is not allowed if FMTCBL is set *This bit is latched by VD.
  [3:0] FMTPLEN0 rw — Number of program entries for SET0 Number of entries = (PLEN0 + 1) Range: 1-16 (FMTCBL = 0) 1-8 (FMTCBL = 1) Setting a value greater than 7 to FMTPLEN1 is not allowed if FMTCBL is set *This bit is latched by VD.
0x11C ISIF_FMTSPH — Input Data Formatter Register
  [12:0] FMTSPH rw — The first pixel in a line fed into the formatter
0x120 ISIF_FMTLNH — Input Data Formatter Register
  [12:0] FMTLNH rw — Number of pixels in a line fed to the formatterNumber of pixels = FMTLNH + 1
0x124 ISIF_FMTLSV — Input Data Formatter Register
  [12:0] FMTSLV rw — Start line vertical
0x128 ISIF_FMTLNV — Input Data Formatter Register
  [14:0] FMTLNV rw — Number of lines in vertical Number of lines = FMTLNV + 1
0x12C ISIF_FMTRLEN — Input Data Formatter Register
  [12:0] FMTRLEN rw — Number of pixels in an output line Maximum value = 4480
0x130 ISIF_FMTHCNT — Input Data Formatter Register
  [12:0] FMTHCNT rw — HD interval for output lines Set all '0' to this register if combining multiple lines into a single line
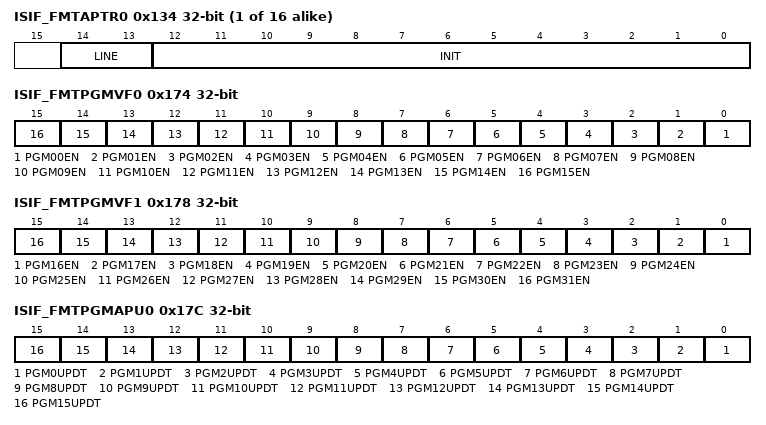
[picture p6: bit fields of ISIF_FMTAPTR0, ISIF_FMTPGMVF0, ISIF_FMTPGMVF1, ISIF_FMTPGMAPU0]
{0x134+4i} ISIF_FMTAPTR{i} (i=0..15) — Input Data Formatter Register
  [14:13] LINE rw — The output line the address belongs to Valid only if FMTCBL is cleared
    0=NEWENUM1 (1st line); 1=NEWENUM2 (2nd line); 3=NEWENUM4 (4th line); 2=NEWENUM3 (3rd line)
  [12:0] INIT rw — Initial address value for address pointer {i} This address can not exceed FMTRLEN - 1
0x174 ISIF_FMTPGMVF0 — Input Data Formatter Register
  [all] fields
    0=NEWENUM1 (Skip this pixel); 1=NEWENUM2 (This pixel is valid)
  [n] PGM{n:02}EN rw (n=0..15) — Program {n} Valid Flag
0x178 ISIF_FMTPGMVF1 — Input Data Formatter Register
  [all] fields
    values as the fields of ISIF_FMTPGMVF0
  [n-16] PGM{n}EN rw (n=16..31) — Program {n} Valid Flag
0x17C ISIF_FMTPGMAPU0 — Input Data Formatter Register
  [all] fields
    0=NEWENUM1 (APTR* + N (Auto increment)); 1=NEWENUM2 (APTR* - N (Auto decrement))
  [n] PGM{n}UPDT rw (n=0..15) — Program {n} Address Pointer Update
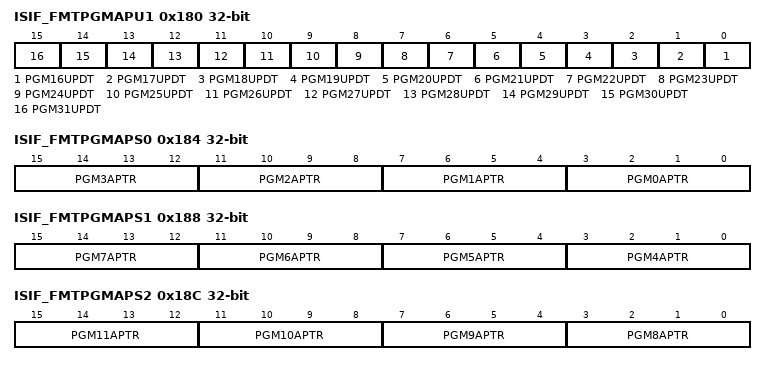
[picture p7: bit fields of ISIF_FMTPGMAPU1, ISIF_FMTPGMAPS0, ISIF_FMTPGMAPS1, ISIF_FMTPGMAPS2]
0x180 ISIF_FMTPGMAPU1 — Input Data Formatter Register
  [all] fields
    values as the fields of ISIF_FMTPGMAPU0
  [n-16] PGM{n}UPDT rw (n=16..31) — Program {n} Address Pointer Update
0x184 ISIF_FMTPGMAPS0 — Input Data Formatter Register
  [4n+3:4n] PGM{n}APTR rw (n=0..3) — Program {n} Address Pointer Select n: APTRn n:0-15 (APTR0 - APR15)
0x188 ISIF_FMTPGMAPS1 — Input Data Formatter Register
  [15:12] PGM7APTR rw — Program 7 Address Pointer Select n: APTRn n:0-15 (APTR0 - APR15)
  [11:8] PGM6APTR rw — Program 6 Address Pointer Select n: APTRn n:0-15 (APTR0 - APR15)
  [7:4] PGM5APTR rw — Program 5 Address Pointer Select n: APTRn n:0-15 (APTR0 - APR15)
  [3:0] PGM4APTR rw — Program 0 Address Pointer Select n: APTRn n:0-15 (APTR0 - APR15)
0x18C ISIF_FMTPGMAPS2 — Input Data Formatter Register
  [4n-29:4n-32] PGM{n}APTR rw (n=8..11) — Program {n} Address Pointer Select n: APTRn n:0-15 (APTR0 - APR15)
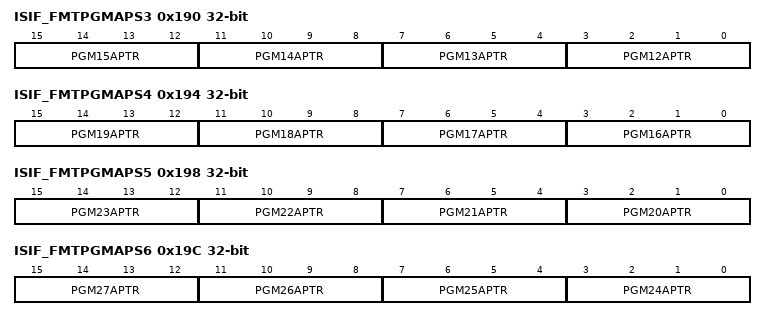
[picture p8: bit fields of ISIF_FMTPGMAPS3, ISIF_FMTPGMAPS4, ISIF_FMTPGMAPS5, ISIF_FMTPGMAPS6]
0x190 ISIF_FMTPGMAPS3 — Input Data Formatter Register
  [4n-45:4n-48] PGM{n}APTR rw (n=12..15) — Program {n} Address Pointer Select n: APTRn n:0-15 (APTR0 - APR15)
0x194 ISIF_FMTPGMAPS4 — Input Data Formatter Register
  [4n-61:4n-64] PGM{n}APTR rw (n=16..19) — Program {n} Address Pointer Select n: APTRn n:0-15 (APTR0 - APR15)
0x198 ISIF_FMTPGMAPS5 — Input Data Formatter Register
  [4n-77:4n-80] PGM{n}APTR rw (n=20..23) — Program {n} Address Pointer Select n: APTRn n:0-15 (APTR0 - APR15)
0x19C ISIF_FMTPGMAPS6 — Input Data Formatter Register
  [4n-93:4n-96] PGM{n}APTR rw (n=24..27) — Program {n} Address Pointer Select n: APTRn n:0-15 (APTR0 - APR15)
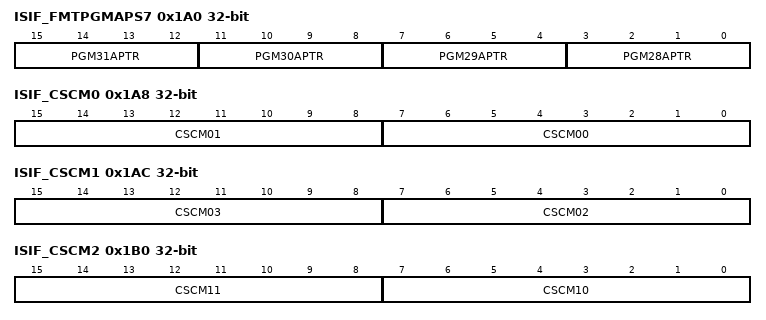
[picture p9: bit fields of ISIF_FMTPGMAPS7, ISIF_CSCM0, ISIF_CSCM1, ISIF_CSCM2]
0x1A0 ISIF_FMTPGMAPS7 — Input Data Formatter Register
  [4n-109:4n-112] PGM{n}APTR rw (n=28..31) — Program {n} Address Pointer Select n: APTRn n:0-15 (APTR0 - APR15)
0x1A4 ISIF_CSCCTL — Color Space Converter Register
  [0] CSCEN rw — Controls ON/OFF of Color Space converter.
    0=NEWENUM1 (Disable); 1=NEWENUM2 (Enable)
0x1A8 ISIF_CSCM0 — Color Space Converter Register
  [15:8] CSCM01 rw — Color Space convert coefficient value M01: This value is signed 8-bit with the 5-bits decimal.
  [7:0] CSCM00 rw — Color Space convert coefficient value M00: This value is signed 8-bit with the 5-bits decimal.
0x1AC ISIF_CSCM1 — Color Space Converter Register
  [15:8] CSCM03 rw — Color Space convert coefficient value M03: This value is signed 8-bit with the 5-bits decimal.
  [7:0] CSCM02 rw — Color Space convert coefficient value M02: This value is signed 8-bit with the 5-bits decimal.
0x1B0 ISIF_CSCM2 — Color Space Converter Register
  [15:8] CSCM11 rw — Color Space convert coefficient value M11: This value is signed 8-bit with the 5-bits decimal.
  [7:0] CSCM10 rw — Color Space convert coefficient value M10: This value is signed 8-bit with the 5-bits decimal.
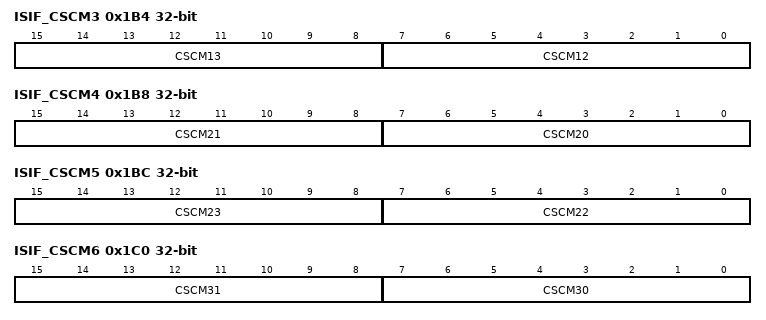
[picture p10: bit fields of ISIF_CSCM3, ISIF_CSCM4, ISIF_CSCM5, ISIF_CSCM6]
0x1B4 ISIF_CSCM3 — Color Space Converter Register
  [15:8] CSCM13 rw — Color Space convert coefficient value M13: This value is signed 8-bit with the 5-bits decimal.
  [7:0] CSCM12 rw — Color Space convert coefficient value M12: This value is signed 8-bit with the 5-bits decimal.
0x1B8 ISIF_CSCM4 — Color Space Converter Register
  [15:8] CSCM21 rw — Color Space convert coefficient value M21: This value is signed 8-bit with the 5-bits decimal.
  [7:0] CSCM20 rw — Color Space convert coefficient value M20: This value is signed 8-bit with the 5-bits decimal.
0x1BC ISIF_CSCM5 — Color Space Converter Register
  [15:8] CSCM23 rw — Color Space convert coefficient value M23: This value is signed 8-bit with the 5-bits decimal.
  [7:0] CSCM22 rw — Color Space convert coefficient value M22: This value is signed 8-bit with the 5-bits decimal.
0x1C0 ISIF_CSCM6 — Color Space Converter Register
  [15:8] CSCM31 rw — Color Space convert coefficient value M31: This value is signed 8-bit with the 5-bits decimal.
  [7:0] CSCM30 rw — Color Space convert coefficient value M30: This value is signed 8-bit with the 5-bits decimal.
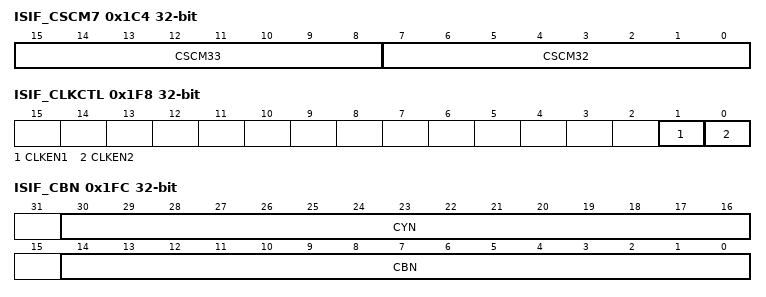
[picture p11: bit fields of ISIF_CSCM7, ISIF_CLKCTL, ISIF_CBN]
0x1C4 ISIF_CSCM7 — Color Space Converter Register
  [15:8] CSCM33 rw — Color Space convert coefficient value M33: This value is signed 8-bit with the 5-bits decimal.
  [7:0] CSCM32 rw — Color Space convert coefficient value M32: This value is signed 8-bit with the 5-bits decimal.
{0x1C8+4i} ISIF_OBWIN{i} ro (i=0..3) — Reserved
{0x1D8+4i} ISIF_OBVAL{i} ro (i=0..7) — Reserved
0x1F8 ISIF_CLKCTL
  [1] CLKEN1 rw — Forces isif_clken1 to be active. (Test mode)
    0=NEWENUM1 (normal mode); 1=NEWENUM2 (force isif_clken1 to be active)
  [0] CLKEN2 rw — Forces isif_clken2 to be active. (Test mode)
    0=NEWENUM1 (normal mode); 1=NEWENUM2 (force isif_clken2 to be active)
0x1FC ISIF_CBN — Circular bufferr parameters.
  [30:16] CYN rw — Cicular Buffer Interrupt timing (line number). After the number lines specified in this field CYN is written to memory, Isif_int_5 (circular buffer interrupt) is issued. Typically, this value is CBN/2 or CBN/4. This value must be even.
  [14:0] CBN rw — Circular buffer size. After CBN lines are written to memory, the address goes back to the start address. If CBN=0, circular buffer function is not used, and address does not go back. This value must be even.
